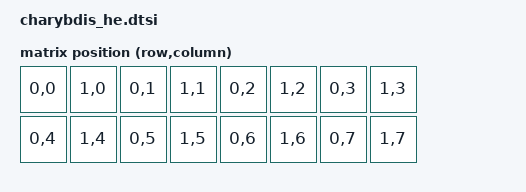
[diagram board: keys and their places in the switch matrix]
// This file was generated from a template. Edit it to match your keyboard.
// See https://zmk.dev/docs/development/hardware-integration/new-shield for more
// instructions.

#include <dt-bindings/zmk/matrix_transform.h>
#include <zephyr/input/input.h>

#include "charybdis_he-layouts.dtsi"

 / {
	chosen {
		zmk,kscan = &he_kscan;
		zmk,physical-layout = &default_layout;
	};

	he_kscan: he_kscan {
		compatible = "he,kscan-multiplexer";
		address-gpios = <&gpio1 15 GPIO_ACTIVE_HIGH>,
			<&gpio1 13 GPIO_ACTIVE_HIGH>,
			<&gpio1 11 GPIO_ACTIVE_HIGH>;
		resolution = <12>;
		wait-period-idle = <5>;
		wait-period-press = <1>;
		calibrate;

		group0 {
			io-channels = <&adc 7>;  // P0.17 Group1/2 MUX1/2
			address-range-min = <0>;
			address-range-max = <7>;
			switch-height = <3300>;
			switch-pressed-is-higher;
		};

		group1 {
			io-channels = <&adc 6>;  // P0.20 Group1/2 MUX3/4
			address-range-min = <0>;
			address-range-max = <7>;
			switch-height = <3300>;
			switch-pressed-is-higher;
		};
	};

	default_transform: default_transform {
		compatible = "zmk,matrix-transform";
		columns = <8>;
		rows = <4>;  // 32 positions for 4 MUX x 8

		map = <
			RC(0,0) RC(1,0) RC(0,1) RC(1,1) RC(0,2) RC(1,2) RC(0,3) RC(1,3)
			RC(0,4) RC(1,4) RC(0,5) RC(1,5) RC(0,6) RC(1,6) RC(0,7) RC(1,7)
		>;
	};
};

&adc {
	status = "okay";
};

&gpio0 {
	status = "okay";
};

&gpio1 {
	status = "okay";
};
